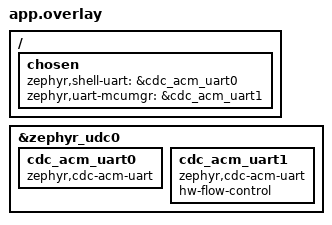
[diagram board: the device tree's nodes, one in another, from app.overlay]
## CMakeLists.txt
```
# Copyright (c) 2026 COBALT Technologies
# SPDX-License-Identifier: Apache-2.0

cmake_minimum_required(VERSION 3.20.0)

# The cb91ai board definition is shared with the watch application
# (firmware/boards), as are the drivers and the wall clock (firmware/lib)
get_filename_component(CB91AI_FIRMWARE_DIR ${CMAKE_CURRENT_SOURCE_DIR}/.. ABSOLUTE)
list(APPEND BOARD_ROOT ${CB91AI_FIRMWARE_DIR})
list(APPEND ZEPHYR_EXTRA_MODULES ${CB91AI_FIRMWARE_DIR}/lib)
# The bindings of the board's parts live with their drivers (firmware/lib/dts)
list(APPEND DTS_ROOT ${CB91AI_FIRMWARE_DIR}/lib)
# Glue around libopus (lot K2): compiles nothing unless CONFIG_CB91AI_OPUS is
# set (bench_opus.conf)
list(APPEND ZEPHYR_EXTRA_MODULES ${CB91AI_FIRMWARE_DIR}/modules/opus)

# Firmware Revision of the Device Information Service = the VERSION file (EF-64):
# a Kconfig fragment written at configure time, so that a phone reads over
# Bluetooth the very version MCUboot and MCUmgr report.
file(READ ${CMAKE_CURRENT_SOURCE_DIR}/VERSION app_version_file)
string(REGEX MATCH "VERSION_MAJOR = ([0-9]+)" _ "${app_version_file}")
set(app_version_major ${CMAKE_MATCH_1})
string(REGEX MATCH "VERSION_MINOR = ([0-9]+)" _ "${app_version_file}")
set(app_version_minor ${CMAKE_MATCH_1})
string(REGEX MATCH "PATCHLEVEL = ([0-9]+)" _ "${app_version_file}")
set(app_version_patch ${CMAKE_MATCH_1})
file(WRITE ${CMAKE_CURRENT_BINARY_DIR}/version.conf
     "CONFIG_BT_DIS_FW_REV_STR=\"${app_version_major}.${app_version_minor}.${app_version_patch}\"\n")
list(APPEND EXTRA_CONF_FILE ${CMAKE_CURRENT_BINARY_DIR}/version.conf)
set_property(DIRECTORY APPEND PROPERTY CMAKE_CONFIGURE_DEPENDS ${CMAKE_CURRENT_SOURCE_DIR}/VERSION)

# Images signed by Zephyr's script, with the address of their slot in the header
set(SIGNING_SCRIPT ${CMAKE_CURRENT_SOURCE_DIR}/cmake/sign.cmake)

find_package(Zephyr REQUIRED HINTS $ENV{ZEPHYR_BASE})
project(cb91ai_firmware LANGUAGES C)

target_sources(app PRIVATE src/main.c src/ble.c src/usb.c src/cmds.c src/lcdwalk.c src/update.c
			   src/remote.c src/hwtest.c)
# Codec bench (lot K2), only in the bench image: -DEXTRA_CONF_FILE=bench_codec.conf
target_sources_ifdef(CONFIG_CB91AI_CODEC_BENCH app PRIVATE src/codec_bench.c)
```

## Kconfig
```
# Copyright (c) 2026 COBALT Technologies
# SPDX-License-Identifier: Apache-2.0
#
# Behaviour of the bench self-test. What it shares with the watch application
# (drivers, wall clock) is in firmware/lib/Kconfig.

config CB91AI_CODEC_BENCH
	bool "Codec bench: flash, RAM and CPU cost of the speech codecs (lot K2)"
	select INIT_STACKS
	select THREAD_STACK_INFO
	help
	  Adds `cb91ai codec ...` (src/codec_bench.c): a couple of seconds of
	  16 kHz speech, synthetic or from the microphone, encoded by each codec
	  built in, with the CPU cycles of every frame (DWT), the size of the
	  encoder state and the stack it really used. IMA ADPCM is always there
	  as a reference; LC3 comes with CONFIG_LIBLC3, Opus with
	  CONFIG_CB91AI_OPUS. A bench image, not a product one: build it with
	  -DEXTRA_CONF_FILE=bench_codec.conf.

if CB91AI_CODEC_BENCH

config CB91AI_CODEC_BENCH_MS
	int "Speech held in RAM for the bench, in milliseconds"
	default 2000
	range 500 4000
	help
	  32 bytes of RAM per millisecond.

config CB91AI_CODEC_BENCH_STACK_SIZE
	int "Stack of the encoder thread, in bytes"
	default 16384
	help
	  Generous on purpose: the bench reports how much of it the encoder
	  used, which is the figure to give the product thread.

config CB91AI_CODEC_BENCH_OPUS_STATE_SIZE
	int "Room for the state of the Opus encoder, in bytes"
	depends on CB91AI_OPUS
	default 40960
	help
	  opus_encoder_get_size() is only known at run time; the bench prints
	  it, and refuses to run when this room is too small.

endif # CB91AI_CODEC_BENCH

config CB91AI_REC_MS
	int "Voice capture held in RAM for `cb91ai rec`, in milliseconds"
	default 0 if CB91AI_CODEC_BENCH
	default 3200
	range 0 4000
	help
	  src/hwtest.c: a capture from the microphone, sent to the PC over
	  Bluetooth by tools/ble_shell.py --wav, for a board sealed in its watch.
	  32 bytes of RAM per millisecond; 0 leaves the command out. The codec
	  bench keeps its own buffer (CB91AI_CODEC_BENCH_MS), hence 0 there.

source "Kconfig.zephyr"
```

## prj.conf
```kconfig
# COBALT CB-91AI bring-up firmware: board self-test over RTT

# Logging and shell over Segger RTT (the board has no UART pads)
CONFIG_LOG=y
CONFIG_LOG_MODE_DEFERRED=y
CONFIG_LOG_BUFFER_SIZE=4096
CONFIG_SHELL=y
CONFIG_SHELL_BACKEND_SERIAL=y
CONFIG_SHELL_PROMPT_UART="cb91ai:~$ "
CONFIG_SHELL_BACKEND_RTT=y
CONFIG_SHELL_PROMPT_RTT="cb91ai:~$ "
CONFIG_SEGGER_RTT_BUFFER_SIZE_UP=8192
# The RTT control block lives in a section that survives resets. Without this
# option stale unread data from the previous run fills the buffer after a
# reflash and the boot log is dropped (NO_BLOCK_SKIP mode).
CONFIG_SEGGER_RTT_INIT_MODE_ALWAYS=y

# Shell helpers for interactive tests (i2c scan, gpio, flash, pwm, adc)
CONFIG_DEVICE_SHELL=y
CONFIG_I2C_SHELL=y
CONFIG_GPIO_SHELL=y
CONFIG_FLASH_SHELL=y
CONFIG_PWM_SHELL=y
CONFIG_ADC_SHELL=y
CONFIG_KERNEL_SHELL=y

# Peripherals exercised by the self-test
CONFIG_GPIO=y
CONFIG_PWM=y
CONFIG_ADC=y
CONFIG_I2C=y
CONFIG_SPI=y
CONFIG_FLASH=y
CONFIG_FLASH_JESD216_API=y
CONFIG_NORDIC_QSPI_NOR=y
CONFIG_REGULATOR=y
# PDM microphone through the dmic API
CONFIG_AUDIO=y
CONFIG_AUDIO_DMIC=y
CONFIG_HWINFO=y
CONFIG_REBOOT=y

CONFIG_MAIN_STACK_SIZE=6144

# USB composite device (new USB device stack, set up in src/usb.c): two
# CDC-ACM ports, the shell and the logs on the first, MCUmgr on the second,
# without the debug probe. VID/PID and strings are in src/usb.c.
CONFIG_SERIAL=y
CONFIG_UART_LINE_CTRL=y
CONFIG_USB_DEVICE_STACK_NEXT=y
CONFIG_USBD_CDC_ACM_CLASS=y
CONFIG_SHELL_BACKEND_SERIAL_CHECK_DTR=y
CONFIG_USBD_CDC_ACM_LOG_LEVEL_OFF=y
# Keep only warnings from the USB stack in the log (Windows probes descriptors
# the device does not have, which is logged as harmless protocol errors)
CONFIG_USBD_LOG_LEVEL_WRN=y
CONFIG_UDC_DRIVER_LOG_LEVEL_WRN=y
# Messages logged before the host opens the COM port wait in this queue
CONFIG_SHELL_BACKEND_SERIAL_LOG_MESSAGE_QUEUE_SIZE=2048

# Bluetooth LE: connectable advertising with the Device Information and Battery
# services, to exercise the 32 MHz crystal and the antenna path (V2-23)
CONFIG_BT=y
CONFIG_BT_PERIPHERAL=y
CONFIG_BT_OBSERVER=y
CONFIG_BT_DEVICE_NAME="CB-91AI"
CONFIG_BT_DEVICE_APPEARANCE=192
CONFIG_BT_MAX_CONN=1
CONFIG_BT_BAS=y
CONFIG_BT_DIS=y
CONFIG_BT_DIS_MODEL_NUMBER_STR="CB-91AI"
CONFIG_BT_DIS_MANUF_NAME_STR="COBALT"
# The revision string comes from the VERSION file, see CMakeLists.txt (EF-64)
CONFIG_BT_DIS_FW_REV=y
CONFIG_BT_DIS_HW_REV=y
CONFIG_BT_DIS_HW_REV_STR="V1"
# 0 dBm by default (EF-31): 4.8 mA peaks instead of 14.8 mA at +8 dBm, which a
# CR2016 feels. `cb91ai txpower <dBm>` raises it at run time for range tests
# (V2-23) through the vendor-specific HCI command.
CONFIG_BT_CTLR_TX_PWR_0=y
CONFIG_BT_CTLR_TX_PWR_DYNAMIC_CONTROL=y
# The 32.768 kHz crystal of the V1 runs fast (10 pF load capacitors for a
# 12.5 pF crystal, V2-02, about +100 ppm expected): declare 250 ppm so that the
# controller widens its receive windows accordingly (EF-39). The default of
# 50 ppm would make the watch miss connection events at long intervals.
CONFIG_CLOCK_CONTROL_NRF_K32SRC_250PPM=y
# Throughput for the BLE firmware image upload (~250 KB): raise the ATT MTU and
# the controller data length so one packet carries a full L2CAP PDU instead of
# 23 bytes, cutting the transfer from minutes to tens of seconds.
CONFIG_BT_L2CAP_TX_MTU=498
CONFIG_BT_BUF_ACL_TX_SIZE=251
CONFIG_BT_BUF_ACL_RX_SIZE=502
CONFIG_BT_CTLR_DATA_LENGTH_MAX=251
# 2M PHY asked for after each connection: half the time on air for the same
# bytes, in an upload as in a voice note later (the Cobalt Link specification). The
# central may refuse; ble.c logs the PHY in force. To weigh against the range
# in the closed case (risk R4): 2M costs a few dB of sensitivity.
CONFIG_BT_AUTO_PHY_PERIPHERAL_2M=y
CONFIG_BT_USER_PHY_UPDATE=y
# RSSI of the connection (HCI Read RSSI), for `cb91ai rssi`: the PC as the
# watch hears it, in the closed case (V2-23, R4)
CONFIG_BT_CTLR_CONN_RSSI=y

# MCUmgr (SMP) over the second USB CDC-ACM port: firmware updates through
# MCUboot, e.g. `smpmgr --port COMx upgrade zephyr.signed.bin`. MCUboot itself
# is built and the image signed by sysbuild (see sysbuild.conf).
CONFIG_NET_BUF=y
CONFIG_ZCBOR=y
CONFIG_CRC=y
CONFIG_BASE64=y
CONFIG_MCUMGR=y
CONFIG_UART_MCUMGR=y
CONFIG_MCUMGR_TRANSPORT_UART=y
# Also expose SMP over Bluetooth LE (nRF Connect Device Manager and the app),
# alongside the USB port kept for the bench (EI-07). The transport registers
# the SMP GATT service (8D53DC1D-...); ble.c advertises its UUID in the scan
# response so the host can find and filter the watch (EF-35, EF-60).
# Reassembly lets an SMP request span several GATT writes (needed once the MTU
# is raised); conn-param control asks for a fast interval during the transfer.
CONFIG_MCUMGR_TRANSPORT_BT=y
CONFIG_MCUMGR_TRANSPORT_BT_REASSEMBLY=y
CONFIG_MCUMGR_TRANSPORT_BT_CONN_PARAM_CONTROL=y
# The BT transport reassembles a whole SMP request into one net_buf, so the
# per-transaction payload is bounded by this buffer, not by the ATT MTU
# (default 384 B would cap the upload chunk regardless of the 498 B MTU). Raise
# it well above the MTU so the host uploads large chunks; clients read the value
# back from os/mcumgr-params. ~2.5 KB x NETBUF_COUNT (4) ~= 10 KB RAM.
CONFIG_MCUMGR_TRANSPORT_NETBUF_SIZE=2475
CONFIG_MCUMGR_GRP_OS=y
CONFIG_MCUMGR_GRP_OS_BOOTLOADER_INFO=y
CONFIG_MCUMGR_GRP_OS_MCUMGR_PARAMS=y
CONFIG_MCUMGR_GRP_IMG=y
CONFIG_IMG_MANAGER=y
# Direct execution with revert (sysbuild.conf). An image flashed over SWD must
# carry a trailer that says "confirmed", or MCUboot erases it: also build
# zephyr.signed.confirmed.hex. An image linked for the other slot is refused at
# the first chunk, thanks to the address imgtool writes in its header (Kconfig),
# and versions are compared down to the build number, as MCUboot does.
CONFIG_MCUBOOT_GENERATE_CONFIRMED_IMAGE=y
CONFIG_MCUMGR_GRP_IMG_REJECT_DIRECT_XIP_MISMATCHED_SLOT=y
CONFIG_MCUMGR_GRP_IMG_VERSION_CMP_USE_BUILD_NUMBER=y
CONFIG_FLASH_MAP=y
CONFIG_STREAM_FLASH=y

# --- Update safety (lot L1, step 2: EF-62 / EF-63) ---
# Task watchdog backed by the nRF WDT (alias watchdog0): the main loop feeds it
# every second. A hung firmware misses the feed, the WDT resets the chip, and
# MCUboot reverts an unconfirmed image at the next boot - the EF-62 revert path.
CONFIG_WATCHDOG=y
CONFIG_TASK_WDT=y
# task_wdt installs the nRF WDT with a window of TASK_WDT_MIN_TIMEOUT +
# HW_FALLBACK_DELAY. That hardware timer keeps counting across the os-reset into
# MCUboot, which validates the incoming image (software SHA-256 + RSA over
# ~270 KB, well over 120 ms) without feeding the WDT. Widen the window far past
# that so a BLE/USB swap is never cut short and bricked into a reset loop; the
# 10 s software channel still catches a hung application.
CONFIG_TASK_WDT_MIN_TIMEOUT=3000
# The task watchdog feeds the hardware one every MIN_TIMEOUT when the
# application is idle, and the hardware window is MIN_TIMEOUT plus this delay.
# The default of 20 ms is thinner than one flash page erase (85 ms with the CPU
# stalled): an update received while the main loop sleeps could be cut by the
# watchdog. One second of margin.
CONFIG_TASK_WDT_HW_FALLBACK_DELAY=1000
# MCUmgr callback hooks: leave the spare slot alone once a host writes or marks
# it (update.c), and show "UPd" on the glass just before the reset (EF-63). No
# battery veto since 0.1.44: same behaviour over the whole range of the CR2016.
CONFIG_MCUMGR_MGMT_NOTIFICATION_HOOKS=y
CONFIG_MCUMGR_GRP_IMG_UPLOAD_CHECK_HOOK=y
# DFU started/pending notifications, for the same spare-slot rule.
CONFIG_MCUMGR_GRP_IMG_STATUS_HOOKS=y
CONFIG_MCUMGR_GRP_OS_RESET_HOOK=y
CONFIG_SYSTEM_WORKQUEUE_STACK_SIZE=2304
CONFIG_SHELL_STACK_SIZE=3072

# --- The link during a flash erase (lot B5) ---
# An update starts with the erase of its slot: 72 pages, 85 ms each, and a plain
# page erase cannot be interrupted. The flash driver books the radio timeline in
# 90 ms slots, connection events are skipped meanwhile, and the link died of its
# supervision timeout in the middle of the erase, one update out of three on
# the bench (reason 0x08, 2026-09-19). Partial erase cuts a page erase in slices
# of 3 ms that the controller interleaves with its connection events; the CPU
# is no longer stalled 85 ms at a time either.
CONFIG_SOC_FLASH_NRF_PARTIAL_ERASE=y
# Supervision timeout asked for: 4 s instead of the 420 ms Zephyr defaults, in
# the preferred parameters (published in the GAP service, requested 5 s after
# the connection) and in the fast parameters MCUmgr requests during a transfer.
# 420 ms is a handful of connection events at 30 to 50 ms: nothing, for a watch
# in a metal case at 0 dBm. Apple wants 2 to 6 s; 4 s is the value of
# the Cobalt Link specification. The central has the last word: ble.c logs what
# is really in force.
CONFIG_BT_PERIPHERAL_PREF_TIMEOUT=400
CONFIG_MCUMGR_TRANSPORT_BT_CONN_PARAM_CONTROL_TIMEOUT=400

# MCUmgr hook for "a command was received": feeds the idle-disconnect timer of
# ble.c, so that a connection is only dropped when the host does nothing.
CONFIG_MCUMGR_SMP_COMMAND_STATUS_HOOKS=y

# --- Idle consumption ---
# Device runtime power management: the QSPI NOR driver then puts the flash in
# deep power-down (about 1 uA instead of 10 to 20 uA in standby) whenever it is
# not in use, and wakes it up for each access (zephyr,pm-device-runtime-auto on
# the flash node of the board devicetree).
CONFIG_PM_DEVICE=y
CONFIG_PM_DEVICE_RUNTIME=y
# The RTT shell polls its input buffer from a timer: the default of 10 ms wakes
# the CPU 100 times a second for a console that is rarely attached.
CONFIG_SHELL_RTT_RX_POLL_PERIOD=250

# --- Shared library (firmware/lib): drivers and wall clock ---
CONFIG_CB91AI_LIB_LCD=y
CONFIG_CB91AI_LIB_MIC=y
CONFIG_CB91AI_LIB_ACCEL=y
CONFIG_CB91AI_LIB_CLOCK=y
# The gestures of the watch (lot D3), tried on the real buttons by
# `cb91ai keys gesture` before the watch application can be installed
CONFIG_CB91AI_LIB_GESTURE=y

# --- Wall clock (lib/clock.c) ---
# Crystal correction stored in the settings (NVS on the storage partition),
# time kept across resets in retained RAM (fixed area of the board devicetree).
CONFIG_SETTINGS=y
CONFIG_SETTINGS_NVS=y
CONFIG_NVS=y
CONFIG_RETAINED_MEM=y
CONFIG_RETENTION=y
# Crystal error of the V1 boards (help of the option in Kconfig): +137.9 ppm
# measured on the bench board on 2026-09-19 with tools/lfxo_drift.py, 40 min
# against NTP, that is 11.9 s a day. Each watch then refines its own value.
CONFIG_CB91AI_CLOCK_DEFAULT_PPB=138000

# V1 board reworked on 2026-09-16 (V2-31): glass COM2 plot bridged to the driver COM0 output
CONFIG_CB91AI_LCD_GLASS_COM2_ON_COM0=y

# HFCLK clock control (also pulled in by the BLE controller).
CONFIG_CLOCK_CONTROL=y

# --- Bench commands over Bluetooth LE (0.1.46) ---
# On a board sealed in its watch there is neither RTT nor USB: the `cb91ai`
# commands, and only them, run from the PC over a GATT service of their own
# (src/remote.c, tools/ble_shell.py), on the dummy shell backend, in the main
# loop. Their output is sent back whole: room for the longest (keys, rec, arm).
# The log stays out of it (RTT and USB carry it).
CONFIG_SHELL_BACKEND_DUMMY=y
CONFIG_SHELL_BACKEND_DUMMY_BUF_SIZE=1600
CONFIG_SHELL_DUMMY_INIT_LOG_LEVEL_NONE=y
```

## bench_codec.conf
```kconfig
# Codec bench image (lot K2): the self-test firmware plus
# `cb91ai codec ...`. Still a regular image: signed, updated over BLE, same
# watchdog and update path. Add the codec to measure with a second fragment,
# one codec per image (they do not fit in RAM together with the speech buffer):
#
#   -DEXTRA_CONF_FILE="bench_codec.conf;bench_lc3.conf"
#   -DEXTRA_CONF_FILE="bench_codec.conf;bench_opus.conf"
#
# The slot 1 variant takes the final .config of the application, so both
# variants get these fragments. On its own, this one only measures IMA ADPCM.

CONFIG_CB91AI_CODEC_BENCH=y
```

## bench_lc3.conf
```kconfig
# Codec bench, LC3 (with bench_codec.conf). liblc3 is a module of the Zephyr
# manifest: `west update --narrow -o=--depth=1 liblc3`. It computes in floating
# point: it wants the FPU and a full libc, and Zephyr builds it with -O3.

CONFIG_FPU=y
CONFIG_LIBLC3=y

# The encoder uses 3.2 kB of stack (measured): with a smaller bench stack there
# is room for 3.2 s of speech, a short sentence for the round trips
# (`cb91ai codec roundtrip`), and the decoder.
CONFIG_CB91AI_CODEC_BENCH_MS=3200
CONFIG_CB91AI_CODEC_BENCH_STACK_SIZE=8192
```

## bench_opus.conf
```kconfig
# Codec bench, Opus (with bench_codec.conf). libopus is not in this repository:
# see firmware/modules/opus/Kconfig. Fixed point, no FPU.

CONFIG_CB91AI_OPUS=y

# Measured on 2026-09-20 (libopus 1.5.2, mono, 16 kHz): the encoder state takes
# 24 548 bytes, and the encoder uses up to 24.7 kB of stack at complexities 0 to
# 5, 26.3 kB at 10. Room for that, and for the same two seconds of speech as
# the LC3 image.
CONFIG_CB91AI_CODEC_BENCH_STACK_SIZE=32768
CONFIG_CB91AI_CODEC_BENCH_OPUS_STATE_SIZE=25600
```

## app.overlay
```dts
/*
 * Copyright (c) 2026 COBALT Technologies
 * SPDX-License-Identifier: Apache-2.0
 *
 * Self-test application overlay: two USB CDC-ACM ports. The first carries a
 * second shell instance (the RTT one stays) and the logs, the second carries
 * the MCUmgr SMP transport used for firmware updates through MCUboot. Both
 * work from a plain COM port, without the debug probe.
 */

/ {
	chosen {
		zephyr,shell-uart = &cdc_acm_uart0;
		zephyr,uart-mcumgr = &cdc_acm_uart1;
	};
};

&zephyr_udc0 {
	cdc_acm_uart0: cdc_acm_uart0 {
		compatible = "zephyr,cdc-acm-uart";
	};

	cdc_acm_uart1: cdc_acm_uart1 {
		compatible = "zephyr,cdc-acm-uart";
		hw-flow-control;
	};
};
```

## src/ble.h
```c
/*
 * Copyright (c) 2026 COBALT Technologies
 * SPDX-License-Identifier: Apache-2.0
 */

#ifndef CB91AI_BLE_H
#define CB91AI_BLE_H

#include <stdbool.h>
#include <stdint.h>

/* Enable Bluetooth and start connectable advertising. The 3 s receiver check
 * (passive scan) is for the bench only: skip it on a coin cell.
 * Returns 0 on success.
 */
int ble_start(bool rx_check_enabled);

/* Update the Battery Service level, 0 to 100 percent. */
void ble_set_battery_level(uint8_t percent);

/* "advertising" or "connected", for the periodic log line. */
const char *ble_state(void);

/* Number of connections accepted since boot. */
unsigned int ble_connect_count(void);

/* HCI reason of the last disconnection since boot, 0 if none. */
uint8_t ble_last_disconnect_reason(void);

/* Update the debug/status characteristic value and notify any subscriber. */
void ble_dbg_set_status(const char *status);

/* Back to fast advertising for 30 s (button press): no-op while connected. In
 * trial mode, a burst instead, unless one runs already. */
void ble_adv_kick(void);

/* Keep fast advertising for `seconds` whenever no host is connected, for a
 * test session on a sealed watch (0: back to normal). An advertising event
 * every 100 to 150 ms instead of every 1 to 1.2 s: some ten times the radio
 * charge of slow advertising while it lasts.
 */
void ble_adv_hold_fast(uint32_t seconds);

/* RSSI of the current connection in dBm: the host as the watch hears it. */
int ble_conn_rssi(int8_t *rssi);

/* "fast", "slow" or "off", and the last advertising error, for the status line. */
const char *ble_adv_mode(void);
int ble_adv_last_error(void);

/* Host activity seen (SMP command, status read): pushes back the idle
 * disconnect of EF-33.
 */
void ble_activity(void);

/* Transmit power in dBm for advertising and the connection (range tests);
 * the controller picks the nearest level it supports.
 */
int ble_set_tx_power(int8_t dbm);
int8_t ble_tx_power(void);

/*
 * Advertising trials (lot N1a, risk R11): how long a phone that keeps a
 * pending connection takes to get in once the watch advertises after a
 * silence. In trial mode the radio is silent between trials, a press on a case
 * button (ble_adv_kick) starts a burst, and the watch times it from its first
 * packet to the connection. See ble.c for the two profiles.
 */
enum ble_trial_profile {
	BLE_TRIAL_APPLE, /* 20 ms for 30 s, then 152.5 ms, then 1022.5 ms */
	BLE_TRIAL_LINK,  /* 100 ms for 10 s, then 1 s (the Cobalt Link specification) */
};

#define BLE_TRIAL_NONE (-1) /* no connection in the window, or no read */
#define BLE_TRIAL_LOG  12   /* trials kept, the oldest dropped first */

struct ble_trial_entry {
	uint32_t number;    /* trials since boot, from 1 */
	uint32_t at_s;      /* uptime at the start of the burst */
	int32_t connect_ms; /* first packet to the connection, or BLE_TRIAL_NONE */
	int32_t read_ms;    /* connection to the first read of the trial value, or NONE */
	uint16_t interval;  /* of the connection, in 1.25 ms units */
	uint16_t latency;
	uint16_t timeout;   /* supervision timeout, in 10 ms units */
	uint8_t profile;    /* enum ble_trial_profile */
	uint8_t step;       /* step of the burst the phone answered, from 0 */
	uint8_t peer[3];    /* last three bytes of the peer address, most significant first */
	uint8_t peer_random;
};

/* What the glass shows: a burst running (its step and time so far), and the
 * last trial, filled even when trial mode is off. False when it is off. */
struct ble_trial_view {
	bool running;
	uint8_t step;
	uint32_t elapsed_ms;
	struct ble_trial_entry last; /* number 0 before the first trial */
};
bool ble_trial_view(struct ble_trial_view *view);

/* Trial mode on, with a profile; it lapses after `lifetime_s` without a trial
 * and normal advertising resumes. -EINVAL on an unknown profile. */
int ble_trial_start(enum ble_trial_profile profile, uint32_t lifetime_s);
void ble_trial_stop(void);
bool ble_trial_mode(void);
bool ble_trial_running(void);
/* A burst as soon as the connected host leaves (a trial run from the PC) */
int ble_trial_go_on_disconnect(void);
/* The trials since boot, oldest first, at most `max`; returns how many */
size_t ble_trial_log(struct ble_trial_entry *out, size_t max);
const char *ble_trial_profile_name(uint8_t profile);
/* Interval of a step of a profile in 0.625 ms units, 0 past the last step */
uint16_t ble_trial_step_interval(uint8_t profile, uint8_t step);

#endif /* CB91AI_BLE_H */
```

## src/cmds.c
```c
/*
 * Copyright (c) 2026 COBALT Technologies
 * SPDX-License-Identifier: Apache-2.0
 *
 * Shell commands to exercise the peripherals on demand, from the RTT shell,
 * the USB console (usb_console.py --cmd "cb91ai mic") or, on a board sealed in
 * its watch, over Bluetooth (ble_shell.py "mic", see remote.c). The checks
 * written for the sealed watch are in hwtest.c.
 */

#include <errno.h>
#include <stdlib.h>
#include <string.h>
#include <zephyr/kernel.h>
#include <zephyr/drivers/pwm.h>
#include <zephyr/shell/shell.h>

#include "accel.h"
#include "ble.h"
#include "clock.h"
#include "codec_bench.h"
#include "hwtest.h"
#include "lcd.h"
#include "lcdwalk.h"
#include "mic.h"

void selftest_clock_enable(bool enable);
void selftest_heartbeat_enable(bool enable);
void selftest_display_hold(bool hold);
bool selftest_display_held(void);

/* RGB LED through PWM (common anode, inverted polarity in the devicetree) */
static const struct pwm_dt_spec pwm_leds[] = {
	PWM_DT_SPEC_GET(DT_NODELABEL(pwm_led_red)),
	PWM_DT_SPEC_GET(DT_NODELABEL(pwm_led_green)),
	PWM_DT_SPEC_GET(DT_NODELABEL(pwm_led_blue)),
};

static int cmd_mic(const struct shell *sh, size_t argc, char **argv)
{
	int ret;

	if (argc >= 2 && strcmp(argv[1], "gain") == 0) {
		if (argc >= 3 && mic_set_gain_db((int)strtol(argv[2], NULL, 10))) {
			shell_print(sh, "gain refused: -20 to 20 dB");
			return -EINVAL;
		}
		shell_print(sh, "microphone gain %+d dB around the PDM default", mic_gain_db());
		return 0;
	}
	ret = mic_test();

	shell_print(sh, "mic test %s (%d), levels are in the log", ret ? "failed" : "done", ret);
	return ret;
}

static int cmd_accel(const struct shell *sh, size_t argc, char **argv)
{
	int32_t mg[3], temp_dc;
	int ret;

	if (argc >= 2 && strcmp(argv[1], "int") == 0) {
		return hwtest_accel_int(sh);
	}
	ret = accel_read(mg, &temp_dc);

	if (ret) {
		shell_print(sh, "accelerometer read failed (%d)", ret);
		return ret;
	}
	shell_print(sh, "x %d y %d z %d mg, temp %d.%d degC", mg[0], mg[1], mg[2], temp_dc / 10,
		    abs(temp_dc % 10));
	return 0;
}

/*
 * Drive settings to compare by eye on the coin cell, VLCD being the rail on the
 * V1 (V2-25, V2-42): all within the datasheet, the first one the default. The
 * high power mode is left out: the datasheet wants VLCD above 3 V for it.
 */
static const struct {
	enum lcd_drive_mode mode;
	bool line_inversion;
	uint16_t frame_hz;
	const char *what;
} lcd_tries[] = {
	{ LCD_DRIVE_NORMAL, false, 65, "normal mode, frame inversion, 65 Hz (the default)" },
	{ LCD_DRIVE_NORMAL, true, 65, "normal mode, line inversion, 65 Hz" },
	{ LCD_DRIVE_NORMAL, false, 52, "normal mode, frame inversion, 52 Hz" },
	{ LCD_DRIVE_NORMAL, false, 86, "normal mode, frame inversion, 86 Hz" },
	{ LCD_DRIVE_NORMAL, false, 130, "normal mode, frame inversion, 130 Hz" },
	{ LCD_DRIVE_POWER_SAVE2, false, 65, "power save mode 2, frame inversion, 65 Hz" },
	{ LCD_DRIVE_POWER_SAVE1, false, 65, "power save mode 1, frame inversion, 65 Hz" },
};
static int lcd_try_at = -1;

/*
 * Apply one setting and show it: "C" top left, its number on the units of the
 * day of month, then 12:34:56 with the chime and PM icons. The number sits on a
 * full digit: the second weekday character shares its verticals, B with C and
 * E with F, and turns a 2 into three bars or a 4 into an H (2026-09-23).
 */
static int lcd_try(const struct shell *sh, int index)
{
	char number[2] = { (char)('1' + index), '\0' };
	int ret = lcd_set_drive_mode(lcd_tries[index].mode);

	ret = ret ? ret : lcd_set_line_inversion(lcd_tries[index].line_inversion);
	ret = ret ? ret : lcd_set_frame_rate(lcd_tries[index].frame_hz);
	lcd_try_at = index;
	selftest_clock_enable(false);
	selftest_display_hold(true);
	lcd_all_pixels(false);
	lcd_clear();
	lcd_display_string("C", 0);
	lcd_display_string(number, 3);
	lcd_display_string("123456", 4);
	lcd_set_colon(true);
	lcd_set_indicator(LCD_INDICATOR_CHIME, true);
	lcd_set_indicator(LCD_INDICATOR_PM, true);
	ret = ret ? ret : lcd_flush();
	shell_print(sh, "C%d: %s (%d)", index + 1, lcd_tries[index].what, ret);
	return ret;
}

static int cmd_lcd(const struct shell *sh, size_t argc, char **argv)
{
	if (argc < 2) {
		shell_print(sh, "usage: cb91ai lcd <text up to 10 chars> | all on | all off | full | "
			    "blank | clock | hold on|off | mode save1|save2|normal | "
			    "frame 130|86|65|52 | inversion line|frame | try <1-7>|next|off | "
			    "duty <3|4> | com <0-3> | com2 on|off | raw [one] <hex>[*n]...");
		return -EINVAL;
	}
	if (strcmp(argv[1], "hold") == 0 && argc >= 3) {
		/* on: display always lit; off: on demand (30 s at boot, 10 s per press) */
		selftest_display_hold(strcmp(argv[2], "on") == 0);
		shell_print(sh, "display %s", selftest_display_held() ? "held on" : "on demand");
		return 0;
	}
	if (strcmp(argv[1], "mode") == 0 && argc >= 3) {
		/* Bias current of the driver, to judge the contrast by eye (EV-05) */
		enum lcd_drive_mode mode = strcmp(argv[2], "save1") == 0 ? LCD_DRIVE_POWER_SAVE1 :
					   strcmp(argv[2], "save2") == 0 ? LCD_DRIVE_POWER_SAVE2 :
									   LCD_DRIVE_NORMAL;
		int ret = lcd_set_drive_mode(mode);

		shell_print(sh, "lcd drive mode %s (%d): x1.0 save1, x1.7 save2, x2.7 normal",
			    argv[2], ret);
		return ret;
	}
	if (strcmp(argv[1], "frame") == 0 && argc >= 3) {
		int ret = lcd_set_frame_rate((unsigned int)atoi(argv[2]));

		shell_print(sh, "lcd frame frequency %s Hz (%d): 130, 86, 65 or 52", argv[2], ret);
		return ret;
	}
	if (strcmp(argv[1], "inversion") == 0 && argc >= 3) {
		int ret = lcd_set_line_inversion(strcmp(argv[2], "line") == 0);

		shell_print(sh, "lcd %s inversion (%d)", strcmp(argv[2], "line") == 0 ? "line" : "frame",
			    ret);
		return ret;
	}
	if (strcmp(argv[1], "try") == 0 && argc >= 3) {
		const int count = ARRAY_SIZE(lcd_tries);

		if (strcmp(argv[2], "off") == 0) {
			/* Back to the default drive and to the clock */
			int ret = lcd_set_drive_mode(LCD_DRIVE_NORMAL);

			ret = ret ? ret : lcd_set_line_inversion(false);
			ret = ret ? ret : lcd_set_frame_rate(65);
			lcd_try_at = -1;
			lcd_all_pixels(false);
			selftest_display_hold(false);
			selftest_clock_enable(true);
			shell_print(sh, "lcd back to C1 and to the clock (%d)", ret);
			return ret;
		}
		if (strcmp(argv[2], "next") == 0) {
			return lcd_try(sh, (lcd_try_at + 1) % count);
		}
		if (atoi(argv[2]) >= 1 && atoi(argv[2]) <= count) {
			return lcd_try(sh, atoi(argv[2]) - 1);
		}
		shell_print(sh, "usage: cb91ai lcd try <1-%d> | next | off", count);
		return -EINVAL;
	}
	if (strcmp(argv[1], "clock") == 0) {
		/* Back to the normal behaviour: uptime clock, display on demand */
		lcd_all_pixels(false);
		selftest_display_hold(false);
		selftest_clock_enable(true);
		return 0;
	}
	/* Every other lcd command is a visual diagnostic: keep the display lit
	 * until `cb91ai lcd clock` (or `lcd hold off`).
	 */
	selftest_display_hold(true);
	if (strcmp(argv[1], "all") == 0 && argc >= 3) {
		return lcd_all_pixels(strcmp(argv[2], "on") == 0);
	}
	if (strcmp(argv[1], "blank") == 0) {
		return lcd_blank();
	}
	if (strcmp(argv[1], "full") == 0) {
		/* Every element through the framebuffer and the glass map of lcd.c,
		 * unlike `all on` (driver test command, RAM untouched): an 8 at each
		 * of the ten positions, the colon and the five icons. The hour tens
		 * (position 4) only draws its "1" on the V1 (SEG18, V2-31). */
		selftest_clock_enable(false);
		lcd_all_pixels(false);
		lcd_clear();
		lcd_display_string("8888888888", 0);
		lcd_set_colon(true);
		for (int i = 0; i < LCD_INDICATOR_COUNT; i++) {
			lcd_set_indicator((enum lcd_indicator)i, true);
		}
		return lcd_flush();
	}
	if (strcmp(argv[1], "duty") == 0 && argc >= 3) {
		int ret = lcd_set_duty(atoi(argv[2]));

		shell_print(sh, "lcd duty 1/%s %s (%d)", argv[2], ret ? "failed" : "set", ret);
		return ret;
	}
	if (strcmp(argv[1], "com2") == 0 && argc >= 3) {
		int ret = lcd_set_glass_com2(strcmp(argv[2], "on") == 0);

		shell_print(sh, "glass COM2 on driver COM0: %s (%d)", lcd_glass_com2() ? "on" : "off", ret);
		return ret;
	}
	if (strcmp(argv[1], "raw") == 0 && argc >= 3) {
		/* raw [one] <hex byte>[*count] ...: RAM bytes as given, "one" = single CS window */
		uint8_t data[LCD_RAW_MAX];
		size_t n = 0;
		int i = 2;
		bool one = strcmp(argv[2], "one") == 0;
		int ret;

		selftest_clock_enable(false);
		lcd_all_pixels(false);
		if (one) {
			i = 3;
		}
		for (; i < argc; i++) {
			char *star = strchr(argv[i], '*');
			int count = star ? atoi(star + 1) : 1;
			uint8_t value = (uint8_t)strtoul(argv[i], NULL, 16);

			while (count-- > 0 && n < sizeof(data)) {
				data[n++] = value;
			}
		}
		ret = lcd_write_raw(data, n, one);
		shell_print(sh, "raw RAM write of %u byte(s) %s (%d)", (unsigned int)n,
			    ret ? "failed" : "done", ret);
		return ret;
	}
	if (strcmp(argv[1], "com") == 0 && argc >= 3) {
		/* Only the segments of that driver COM line, all of them */
		selftest_clock_enable(false);
		lcd_all_pixels(false);
		lcd_clear();
		lcd_fill_com(atoi(argv[2]), true);
		return lcd_flush();
	}
	selftest_clock_enable(false);
	lcd_all_pixels(false);
	lcd_clear();
	lcd_display_string(argv[1], 0);
	return lcd_flush();
}

static int cmd_pixel(const struct shell *sh, size_t argc, char **argv)
{
	if (argc < 3) {
		shell_print(sh, "usage: cb91ai pixel <com 0-2> <seg 0-23> [off]");
		return -EINVAL;
	}
	selftest_clock_enable(false);
	selftest_display_hold(true);
	lcd_set_pixel(atoi(argv[1]), atoi(argv[2]), argc < 4 || strcmp(argv[3], "off") != 0);
	return lcd_flush();
}

static int cmd_walk(const struct shell *sh, size_t argc, char **argv)
{
	int ret = 0;

	if (argc < 2) {
		shell_print(sh, "usage: cb91ai walk start [pixel|seg] [step] | next | prev | goto <step> | "
			    "stop | status");
		return -EINVAL;
	}
	if (strcmp(argv[1], "start") == 0) {
		enum lcdwalk_unit unit = (argc >= 3 && strcmp(argv[2], "seg") == 0) ? LCDWALK_SEG
									     : LCDWALK_PIXEL;

		if (ble_trial_mode()) {
			/* The walk polls the buttons with their interrupts off: in trial
			 * mode no press could start a burst, and the watch would stay silent */
			shell_print(sh, "refused: the advertising trials need the buttons (adv trial off)");
			return -EBUSY;
		}
		ret = lcdwalk_start(unit, argc >= 4 ? atoi(argv[3]) - 1 : 0);
		shell_print(sh, "walk %s (%d): MODE next, LIGHT previous, ALARM next COM line, "
			    "steps in the log", ret ? "failed" : "started", ret);
	} else if (strcmp(argv[1], "next") == 0) {
		ret = lcdwalk_move(1);
	} else if (strcmp(argv[1], "prev") == 0) {
		ret = lcdwalk_move(-1);
	} else if (strcmp(argv[1], "goto") == 0 && argc >= 3) {
		ret = lcdwalk_goto(atoi(argv[2]) - 1);
	} else if (strcmp(argv[1], "stop") == 0) {
		lcdwalk_stop();
	} else if (strcmp(argv[1], "status") != 0) {
		return -EINVAL;
	}
	shell_print(sh, "walk %s, step %d/%d", lcdwalk_active() ? "active" : "stopped",
		    lcdwalk_step() + 1, lcdwalk_count());
	return ret;
}

static int cmd_led(const struct shell *sh, size_t argc, char **argv)
{
	static const struct {
		const char *name;
		uint8_t mask; /* bit 0 red, bit 1 green, bit 2 blue */
	} colors[] = {
		{ "off", 0 }, { "red", 1 }, { "green", 2 }, { "yellow", 3 }, { "blue", 4 },
		{ "magenta", 5 }, { "cyan", 6 }, { "white", 7 },
	};
	long percent = argc >= 3 ? strtol(argv[2], NULL, 10) : 100;
	long ms = argc >= 4 ? strtol(argv[3], NULL, 10) : 0;
	struct hwtest_rail rail;
	int ret = 0;
	int found = -1;

	if (argc < 2) {
		shell_print(sh, "usage: cb91ai led <off|red|green|blue|yellow|magenta|cyan|white> "
			    "[percent] [ms] | led hue");
		return -EINVAL;
	}
	if (strcmp(argv[1], "hue") == 0) {
		/* The colour wheel of the boot, with the rail */
		selftest_heartbeat_enable(false);
		ret = hwtest_led_hue(&rail);
		shell_print(sh, "LED hue: one turn of the colour wheel in 1.5 s (%d): rail %d mV before, "
			    "lowest %d mV (%u readings), %d mV after", ret, rail.before_mv,
			    rail.lowest_mv, rail.readings, rail.after_mv);
		return ret;
	}
	/* On a coin cell the LED only lights in pulses (specification 4.7): at
	 * most 1 s, 300 ms when no duration is given. On USB it stays lit unless
	 * a duration is given. */
	if (!hwtest_on_usb()) {
		ms = ms <= 0 ? 300 : MIN(ms, 1000);
	}
	for (size_t i = 0; i < ARRAY_SIZE(colors); i++) {
		if (strcmp(argv[1], colors[i].name) == 0) {
			found = i;
		}
	}
	if (found < 0 || percent < 0 || percent > 100) {
		return -EINVAL;
	}
	selftest_heartbeat_enable(false);
	(void)hwtest_rail_mv(&rail.before_mv);
	for (size_t i = 0; i < ARRAY_SIZE(pwm_leds) && !ret; i++) {
		uint32_t pulse = (colors[found].mask & BIT(i)) ?
				 (uint32_t)((uint64_t)pwm_leds[i].period * percent / 100) : 0;

		ret = pwm_set_pulse_dt(&pwm_leds[i], pulse);
	}
	if (ms <= 0 || found == 0) {
		shell_print(sh, "LED %s at %ld %% (%d), heartbeat off", colors[found].name, percent,
			    ret);
		return ret;
	}
	/* A pulse: the rail is watched while it lasts, then everything is off */
	hwtest_rail_watch(&rail, (uint32_t)ms);
	for (size_t i = 0; i < ARRAY_SIZE(pwm_leds); i++) {
		(void)pwm_set_pulse_dt(&pwm_leds[i], 0);
	}
	k_msleep(3);
	(void)hwtest_rail_mv(&rail.after_mv);
	shell_print(sh, "LED %s at %ld %% for %ld ms (%d): rail %d mV before, lowest %d mV, "
		    "%d mV after", colors[found].name, percent, ms, ret, rail.before_mv,
		    rail.lowest_mv, rail.after_mv);
	return ret;
}

static int cmd_txpower(const struct shell *sh, size_t argc, char **argv)
{
	if (argc >= 2) {
		int ret = ble_set_tx_power((int8_t)strtol(argv[1], NULL, 10));

		if (ret) {
			shell_print(sh, "tx power not set (%d)", ret);
			return ret;
		}
	}
	shell_print(sh, "tx power %d dBm (0 by default, up to 8 for range tests)", ble_tx_power());
	return 0;
}

static int cmd_time(const struct shell *sh, size_t argc, char **argv)
{
	struct tm tm;

	if (argc >= 3 && strcmp(argv[1], "set") == 0) {
		/* time set <UTC seconds since 1970> [local offset in minutes] */
		clock_set(strtoll(argv[2], NULL, 10) * 1000,
			  argc >= 4 ? (int16_t)strtol(argv[3], NULL, 10) : clock_tz_minutes(), false);
	} else if (argc >= 3 && strcmp(argv[1], "ppb") == 0) {
		int ret = clock_set_ppb((int32_t)strtol(argv[2], NULL, 10));

		if (ret) {
			shell_print(sh, "correction refused (%d): +/-1000000 ppb at most", ret);
			return ret;
		}
	} else if (argc >= 3 && strcmp(argv[1], "format") == 0) {
		clock_set_24h(strcmp(argv[2], "24") == 0);
	} else if (argc >= 2) {
		shell_print(sh, "usage: cb91ai time | time set <utc seconds> [tz minutes] | "
			    "time ppb <ppb> | time format 12|24");
		return -EINVAL;
	}
	if (clock_local_tm(&tm)) {
		shell_print(sh, "%04d-%02d-%02d %02d:%02d:%02d local (UTC%+d min), utc ms %lld%s",
			    tm.tm_year + 1900, tm.tm_mon + 1, tm.tm_mday, tm.tm_hour, tm.tm_min,
			    tm.tm_sec, clock_tz_minutes(), clock_now_ms(),
			    (clock_flags() & CLOCK_FLAG_APPROXIMATE) ? ", approximate (restored)" : "");
	} else {
		shell_print(sh, "time not set");
	}
	{
		char digits[7];
		bool pm;

		if (clock_display(digits, &pm, &tm)) {
			shell_print(sh, "glass: \"%c%c:%c%c %c%c\"%s, %s-hour format", digits[0],
				    digits[1], digits[2], digits[3], digits[4], digits[5],
				    pm ? " PM" : "", clock_24h() ? "24" : "12");
		}
	}
	shell_print(sh, "crystal correction %d ppb (%s), uptime %lld ms", clock_ppb(),
		    (clock_flags() & CLOCK_FLAG_CALIBRATED) ? "stored or calibrated" : "board default",
		    k_uptime_get());
	return 0;
}

static int cmd_heartbeat(const struct shell *sh, size_t argc, char **argv)
{
	bool on = argc >= 2 && strcmp(argv[1], "on") == 0;

	if (on) {
		for (size_t i = 0; i < ARRAY_SIZE(pwm_leds); i++) {
			pwm_set_pulse_dt(&pwm_leds[i], 0);
		}
	}
	selftest_heartbeat_enable(on);
	shell_print(sh, "green heartbeat %s", on ? "on" : "off");
	return 0;
}

SHELL_STATIC_SUBCMD_SET_CREATE(sub_cb91ai,
	SHELL_CMD(mic, NULL, "mic: capture and log the level | mic gain [dB]: PDM gain, -20 to 20", cmd_mic),
	SHELL_CMD(accel, NULL, "accel: read the accelerometer and its temperature | accel int: check "
		  "its two interrupt lines", cmd_accel),
	SHELL_CMD(lcd, NULL, "lcd <text> | all on|off | full | blank | clock | hold on|off | mode <m> | "
		  "frame <Hz> | inversion line|frame | try <n>|next|off | duty <3|4> | com <0-3>",
		  cmd_lcd),
	SHELL_CMD(time, NULL, "time | time set <utc s> [tz min] | time ppb <ppb> | time format 12|24", cmd_time),
	SHELL_CMD(txpower, NULL, "txpower [dBm]: radio transmit power, -40 to 8", cmd_txpower),
	SHELL_CMD(led, NULL, "led <off|red|green|blue|yellow|magenta|cyan|white> [percent] [ms]: "
		  "pulses only on the coin cell | led hue: the colour wheel of the boot", cmd_led),
	SHELL_CMD(heartbeat, NULL, "heartbeat on|off: green blink every second (off at boot)", cmd_heartbeat),
	SHELL_CMD(walk, NULL, "walk start [pixel|seg] [step] | next | prev | goto <n> | stop | status", cmd_walk),
	SHELL_CMD(pixel, NULL, "pixel <com> <seg> [off]: one LCD segment by COM and F-91W SEG", cmd_pixel),
	SHELL_CMD(keys, NULL, "keys | keys probe [s] | keys stop: case buttons read with both pulls | "
		  "keys gesture <s> | gesture | gesture stop: their gestures on the glass (lot D3)",
		  hwtest_cmd_keys),
	SHELL_CMD(beep, NULL, "beep <Hz> [ms] [duty percent] | beep sweep | beep ladder | beep alarm, "
		  "\"force\" last for full power on the coin cell: buzzer, with the rail", hwtest_cmd_beep),
	SHELL_CMD(rec, NULL, "rec [ms] | rec get | rec info: voice capture in RAM, sent over BLE",
		  hwtest_cmd_rec),
	SHELL_CMD(take, NULL, "take <1-5> [ms] | take get <1-5> | take info: voice take of up to 6 s "
		  "in the storage flash, sent over BLE", hwtest_cmd_take),
	SHELL_CMD(arm, NULL, "arm <n> <command...> | arm off | arm: a command at the next n presses "
		  "of ALARM", hwtest_cmd_arm),
	SHELL_CMD(rssi, NULL, "rssi: the host as the watch hears it", hwtest_cmd_rssi),
	SHELL_CMD(qspi, NULL, "qspi: erase, write and read back the last sector of the storage flash",
		  hwtest_cmd_qspi),
	SHELL_CMD(adv, NULL, "adv fast <min> | adv normal: fast advertising for a test session | "
		  "adv trial apple|link [min] | trial go | trial off | trial: bursts timed to a "
		  "phone's connection (lot N1a)", hwtest_cmd_adv),
	SHELL_COND_CMD(CONFIG_CB91AI_CODEC_BENCH, codec, NULL,
		       "codec signal | record [raw] | level | all | adpcm | lc3 <bit/s> [frame us] | "
		       "opus <bit/s> [complexity] [frame ms] [nb|mb|wb] | dump | "
		       "roundtrip adpcm | roundtrip lc3 <bit/s> [frame us]", codec_bench_cmd),
	SHELL_SUBCMD_SET_END);
SHELL_CMD_REGISTER(cb91ai, &sub_cb91ai, "CB-91AI self-test commands", NULL);
```

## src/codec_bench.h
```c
/*
 * Copyright (c) 2026 COBALT Technologies
 * SPDX-License-Identifier: Apache-2.0
 */

#ifndef CB91AI_CODEC_BENCH_H
#define CB91AI_CODEC_BENCH_H

#include <zephyr/shell/shell.h>

/*
 * `cb91ai codec ...`: cost of the candidate speech codecs on this board (lot
 * K2). Only built with CONFIG_CB91AI_CODEC_BENCH, see src/codec_bench.c.
 */
int codec_bench_cmd(const struct shell *sh, size_t argc, char **argv);

#endif /* CB91AI_CODEC_BENCH_H */
```

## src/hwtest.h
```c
/*
 * Copyright (c) 2026 COBALT Technologies
 * SPDX-License-Identifier: Apache-2.0
 */

#ifndef CB91AI_HWTEST_H
#define CB91AI_HWTEST_H

#include <stdbool.h>
#include <stddef.h>
#include <stdint.h>
#include <zephyr/shell/shell.h>

/* The 3V rail around a load: before it, lowest while it lasts, after it */
struct hwtest_rail {
	int32_t before_mv;
	int32_t lowest_mv;
	int32_t after_mv;
	uint32_t readings;
};

/* Read the rail (SAADC, VDD input) as fast as it goes for `ms` milliseconds,
 * keeping the lowest reading: the load is switched on by the caller before,
 * and off after. Fills `lowest_mv` and `readings` only.
 */
void hwtest_rail_watch(struct hwtest_rail *rail, uint32_t ms);
int hwtest_rail_mv(int32_t *mv);

/* USB power present: the bench, where the limits of a coin cell do not apply */
bool hwtest_on_usb(void);

/* One turn of the colour wheel on the RGB LED in 1.5 s, the LEDs at boot and
 * `cb91ai led hue`; the rail is watched meanwhile when `rail` is not NULL */
int hwtest_led_hue(struct hwtest_rail *rail);

/* From the main loop: the ALARM button was pressed (runs an armed command) */
void hwtest_alarm_pressed(void);

/* From the main loop, in trial mode (lot N1a): the glass as a stopwatch of the
 * burst, then its result; a short pulse of the green LED for a connection, of
 * the red one for a trial without */
struct ble_trial_view;
void hwtest_trial_show(const struct ble_trial_view *view);
void hwtest_trial_cue(bool connected);

/* Shell commands, registered in cmds.c */
int hwtest_cmd_keys(const struct shell *sh, size_t argc, char **argv);
int hwtest_cmd_beep(const struct shell *sh, size_t argc, char **argv);
int hwtest_cmd_rec(const struct shell *sh, size_t argc, char **argv);
int hwtest_cmd_take(const struct shell *sh, size_t argc, char **argv);
int hwtest_cmd_arm(const struct shell *sh, size_t argc, char **argv);
int hwtest_cmd_rssi(const struct shell *sh, size_t argc, char **argv);
int hwtest_cmd_adv(const struct shell *sh, size_t argc, char **argv);

/* `cb91ai accel int`: the INT1 and INT2 lines of the BMA400 */
int hwtest_accel_int(const struct shell *sh);

/* `cb91ai qspi`: erase, write and read back the last sector of the storage flash */
int hwtest_cmd_qspi(const struct shell *sh, size_t argc, char **argv);

#endif /* CB91AI_HWTEST_H */
```

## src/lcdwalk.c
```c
/*
 * Copyright (c) 2026 COBALT Technologies
 * SPDX-License-Identifier: Apache-2.0
 *
 * LCD segment walk: lights one pixel of the glass (COM, SEG) at a time, or
 * one SEG plot with its three COM lines, and moves on when a case button is
 * pressed (MODE next, LIGHT previous, ALARM next COM line) or from the shell
 * (cb91ai walk ...). Each step is logged with the element the Sensor Watch
 * map expects there, so that one photo per step maps the glass. The blue LED
 * flashes on every accepted press.
 *
 * The polarity of the case buttons is not known (V2-22): every 20 ms each
 * input is read with a pull-up then with a pull-down; a level that follows
 * neither pull is a pressed button, and the log says which rail it went to.
 */

#include <errno.h>
#include <string.h>
#include <zephyr/kernel.h>
#include <zephyr/drivers/gpio.h>
#include <zephyr/logging/log.h>

#include "lcd.h"
#include "lcdwalk.h"

LOG_MODULE_REGISTER(cb91ai_walk, LOG_LEVEL_INF);

void selftest_clock_enable(bool enable);
void selftest_display_hold(bool hold);
void selftest_buttons_irq(bool enable);

#define GLASS_COMS       3
#define GLASS_SEGS       24
#define POLL_MS          20
#define DEBOUNCE_SAMPLES 3
#define FLASH_MS         80

enum { BTN_LIGHT, BTN_MODE, BTN_ALARM, BTN_COUNT };

static const struct gpio_dt_spec buttons[BTN_COUNT] = {
	GPIO_DT_SPEC_GET(DT_NODELABEL(button_light), gpios),
	GPIO_DT_SPEC_GET(DT_NODELABEL(button_mode), gpios),
	GPIO_DT_SPEC_GET(DT_NODELABEL(button_alarm), gpios),
};
static const char *const button_names[BTN_COUNT] = { "LIGHT", "MODE", "ALARM" };
static const struct gpio_dt_spec led = GPIO_DT_SPEC_GET(DT_NODELABEL(led_blue), gpios);

static struct {
	bool active;
	enum lcdwalk_unit unit;
	int step;
	int count;
	uint8_t held[BTN_COUNT]; /* consecutive samples seen pressed */
	bool pressed[BTN_COUNT];
} walk;

static struct k_work_delayable poll_work;
static struct k_work_delayable led_work;
static bool works_ready;

static void led_off(struct k_work *work)
{
	gpio_pin_set_dt(&led, 0);
}

static void flash(void)
{
	gpio_pin_set_dt(&led, 1);
	k_work_reschedule(&led_work, K_MSEC(FLASH_MS));
}

static void show_step(void)
{
	char what[80];
	int com, seg;

	lcd_all_pixels(false);
	lcd_clear();
	if (walk.unit == LCDWALK_PIXEL) {
		com = walk.step / GLASS_SEGS;
		seg = walk.step % GLASS_SEGS;
		lcd_set_pixel(com, seg, true);
		lcd_describe_pixel(com, seg, what, sizeof(what));
		LOG_INF("walk %d/%d: COM%d SEG%d = %s", walk.step + 1, walk.count, com, seg, what);
	} else {
		seg = walk.step;
		for (com = 0; com < GLASS_COMS; com++) {
			lcd_set_pixel(com, seg, true);
		}
		LOG_INF("walk %d/%d: SEG%d on COM0 to COM2", walk.step + 1, walk.count, seg);
		for (com = 0; com < GLASS_COMS; com++) {
			lcd_describe_pixel(com, seg, what, sizeof(what));
			LOG_INF("  COM%d = %s", com, what);
		}
	}
	lcd_flush();
}

static void act(int button)
{
	flash();
	switch (button) {
	case BTN_MODE:
		lcdwalk_move(1);
		break;
	case BTN_LIGHT:
		lcdwalk_move(-1);
		break;
	case BTN_ALARM:
		if (walk.unit == LCDWALK_PIXEL) {
			lcdwalk_goto(((walk.step / GLASS_SEGS + 1) % GLASS_COMS) * GLASS_SEGS);
		} else {
			lcdwalk_move(8);
		}
		break;
	default:
		break;
	}
}

static void poll(struct k_work *work)
{
	for (int i = 0; i < BTN_COUNT; i++) {
		int up, down;

		/* Pull-up first, pull-down last: the pin rests in its devicetree state */
		gpio_pin_configure(buttons[i].port, buttons[i].pin, GPIO_INPUT | GPIO_PULL_UP);
		k_busy_wait(50);
		up = gpio_pin_get_raw(buttons[i].port, buttons[i].pin);
		gpio_pin_configure(buttons[i].port, buttons[i].pin, GPIO_INPUT | GPIO_PULL_DOWN);
		k_busy_wait(50);
		down = gpio_pin_get_raw(buttons[i].port, buttons[i].pin);

		bool now = (down == 1) || (up == 0);

		walk.held[i] = now ? MIN(walk.held[i] + 1, DEBOUNCE_SAMPLES) : 0;
		if (!walk.pressed[i] && walk.held[i] == DEBOUNCE_SAMPLES) {
			walk.pressed[i] = true;
			LOG_INF("%s pressed (contact to %s)", button_names[i],
				down == 1 ? "VDD" : "GND");
			act(i);
		} else if (walk.pressed[i] && walk.held[i] == 0) {
			walk.pressed[i] = false;
		}
	}
	if (walk.active) {
		k_work_reschedule(&poll_work, K_MSEC(POLL_MS));
	}
}

int lcdwalk_start(enum lcdwalk_unit unit, int step)
{
	int ret;

	for (int i = 0; i < BTN_COUNT; i++) {
		if (!gpio_is_ready_dt(&buttons[i])) {
			return -ENODEV;
		}
	}
	if (!works_ready) {
		k_work_init_delayable(&poll_work, poll);
		k_work_init_delayable(&led_work, led_off);
		works_ready = true;
	}
	ret = gpio_pin_configure_dt(&led, GPIO_OUTPUT_INACTIVE);
	if (ret) {
		return ret;
	}
	selftest_clock_enable(false);
	/* Steady display for the photos, and no wake-up interrupts while the
	 * inputs are probed with both pulls
	 */
	selftest_display_hold(true);
	selftest_buttons_irq(false);
	walk.unit = unit;
	walk.count = unit == LCDWALK_PIXEL ? GLASS_COMS * GLASS_SEGS : GLASS_SEGS;
	walk.step = CLAMP(step, 0, walk.count - 1);
	memset(walk.held, 0, sizeof(walk.held));
	memset(walk.pressed, 0, sizeof(walk.pressed));
	walk.active = true;
	LOG_INF("walk started, %s mode, %d steps: MODE next, LIGHT previous, ALARM next COM",
		unit == LCDWALK_PIXEL ? "pixel" : "seg", walk.count);
	show_step();
	k_work_reschedule(&poll_work, K_MSEC(POLL_MS));
	return 0;
}

int lcdwalk_move(int delta)
{
	int next;

	if (!walk.active) {
		return lcdwalk_start(LCDWALK_PIXEL, 0);
	}
	next = ((walk.step + delta) % walk.count + walk.count) % walk.count;
	if ((delta > 0 && next < walk.step) || (delta < 0 && next > walk.step)) {
		LOG_INF("walk: wrapped around");
	}
	walk.step = next;
	show_step();
	return 0;
}

int lcdwalk_goto(int step)
{
	if (!walk.active) {
		return lcdwalk_start(LCDWALK_PIXEL, step);
	}
	walk.step = CLAMP(step, 0, walk.count - 1);
	show_step();
	return 0;
}

void lcdwalk_stop(void)
{
	if (!walk.active) {
		return;
	}
	walk.active = false;
	k_work_cancel_delayable(&poll_work);
	for (int i = 0; i < BTN_COUNT; i++) {
		gpio_pin_configure_dt(&buttons[i], GPIO_INPUT);
	}
	gpio_pin_set_dt(&led, 0);
	lcd_all_pixels(false);
	selftest_buttons_irq(true);
	selftest_display_hold(false);
	selftest_clock_enable(true);
	LOG_INF("walk stopped, clock back");
}

bool lcdwalk_active(void)
{
	return walk.active;
}

int lcdwalk_step(void)
{
	return walk.step;
}

int lcdwalk_count(void)
{
	return walk.count;
}
```
